# ATmega8A register map
Vendor: Atmel; File version: 1.0
CPU: other r0p0, little endian, no MPU, no FPU, 4 interrupt priority bits
Registers are 8-bit, read-write, reset 0x0 unless marked. A register's access mark holds for its fields unless they carry their own. Offsets are from the block's base; lines under a group give offsets from that group; [hi:lo] are bit positions; {n}, {i} and the like mark numbered series; 'fields as' and 'values as' point back to an identical list; <NAME> marks a mode.

## Memory map
0x00000000 FUSE size 0x2 — Fuses
0x00000000 LOCKBIT size 0x1 — Lockbits
0x00000020 TWI blocks up to offset 0x37 — Two Wire Serial Interface
0x00000024 ADC size 0x4 — Analog-to-Digital Converter
0x00000028 AC blocks up to offset 0x29 — Analog Comparator
0x00000029 USART blocks up to offset 0x18
0x0000002D SPI size 0x3 — Serial Peripheral Interface
0x00000030 PORTD size 0x3 — I/O Port
0x00000033 PORTC size 0x3 — I/O Port
0x00000036 PORTB size 0x3 — I/O Port
0x0000003C EEPROM size 0x4
0x00000041 WDT size 0x1 — Watchdog Timer
0x00000042 TC2 blocks up to offset 0x18 — Timer/Counter, 8-bit Async
0x00000046 TC1 blocks up to offset 0x14 — Timer/Counter, 16-bit
0x00000050 CPU blocks up to offset 0x8 — CPU Registers
0x00000052 TC0 blocks up to offset 0x8 — Timer/Counter, 8-bit
0x00000055 EXINT blocks up to offset 0x7 — External Interrupts

## Interrupts
0 RESET (CPU) — External Pin, Power-on Reset, Brown-out Reset and Watchdog Reset
1 INT0 (CPU) — External Interrupt Request 0
2 INT1 (CPU) — External Interrupt Request 1
3 TIMER2_COMP (CPU) — Timer/Counter2 Compare Match
4 TIMER2_OVF (CPU) — Timer/Counter2 Overflow
5 TIMER1_CAPT (CPU) — Timer/Counter1 Capture Event
6 TIMER1_COMPA (CPU) — Timer/Counter1 Compare Match A
7 TIMER1_COMPB (CPU) — Timer/Counter1 Compare Match B
8 TIMER1_OVF (CPU) — Timer/Counter1 Overflow
9 TIMER0_OVF (CPU) — Timer/Counter0 Overflow
10 SPI_STC (CPU) — Serial Transfer Complete
11 USART_RXC (CPU) — USART, Rx Complete
12 USART_UDRE (CPU) — USART Data Register Empty
13 USART_TXC (CPU) — USART, Tx Complete
14 ADC (CPU) — ADC Conversion Complete
15 EE_RDY (CPU) — EEPROM Ready
16 ANA_COMP (CPU) — Analog Comparator
17 TWI (CPU) — 2-wire Serial Interface
18 SPM_RDY (CPU) — Store Program Memory Ready

## AC — Analog Comparator
Base 0x00000028
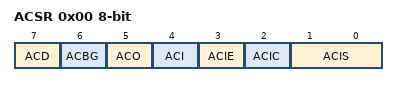
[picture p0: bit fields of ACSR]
0x00 ACSR — Analog Comparator Control And Status Register
  [7] ACD — Analog Comparator Disable
  [6] ACBG — Analog Comparator Bandgap Select
  [5] ACO — Analog Compare Output
  [4] ACI — Analog Comparator Interrupt Flag
  [3] ACIE — Analog Comparator Interrupt Enable
  [2] ACIC — Analog Comparator Input Capture Enable
  [1:0] ACIS — Analog Comparator Interrupt Mode Select bits
    0=Interrupt on Toggle; 2=Interrupt on Falling Edge; 3=Interrupt on Rising Edge
0x28 SFIOR — Special Function IO Register
  [3] ACME — Analog Comparator Multiplexer Enable

## ADC — Analog-to-Digital Converter
Base 0x00000024
0x00 ADC 16-bit (reset mask 0xFF) — ADC Data Register Bytes
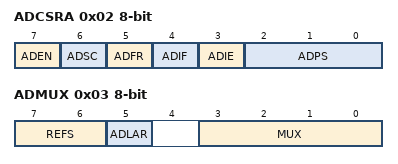
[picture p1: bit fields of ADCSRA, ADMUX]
0x02 ADCSRA — The ADC Control and Status register
  [7] ADEN — ADC Enable
  [6] ADSC — ADC Start Conversion
  [5] ADFR — ADC Free Running Select
  [4] ADIF — ADC Interrupt Flag
  [3] ADIE — ADC Interrupt Enable
  [2:0] ADPS — ADC Prescaler Select Bits
    0=2; 1=2; 2=4; 3=8; 4=16; 5=32; 6=64; 7=128
0x03 ADMUX — The ADC multiplexer Selection Register
  [7:6] REFS — Reference Selection Bits
    0=AREF, Internal Vref turned off; 1=AVCC with external capacitor at AREF pin; 3=Internal 2.56V Voltage Reference with external capacitor at AREF pin
  [5] ADLAR — Left Adjust Result
  [3:0] MUX — Analog Channel and Gain Selection Bits

## CPU — CPU Registers
Base 0x00000050
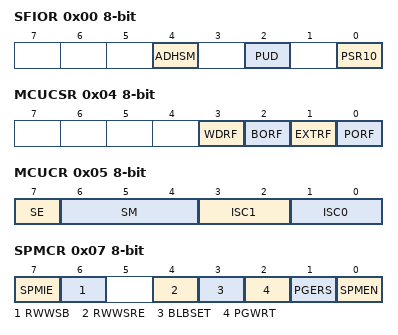
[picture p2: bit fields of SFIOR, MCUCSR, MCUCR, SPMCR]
0x00 SFIOR — Special Function IO Register
  [4] ADHSM — ADC High Speed Mode
  [2] PUD — Pull-up Disable
  [0] PSR10 — Prescaler Reset Timer/Counter1 and Timer/Counter0
0x01 OSCCAL — Oscillator Calibration Value
  [7:0] OSCCAL — Oscillator Calibration
0x04 MCUCSR — MCU Control And Status Register
  [3] WDRF — Watchdog Reset Flag
  [2] BORF — Brown-out Reset Flag
  [1] EXTRF — External Reset Flag
  [0] PORF — Power-on reset flag
0x05 MCUCR — MCU Control Register
  [7] SE — Sleep Enable
  [6:4] SM — Sleep Mode Select
    0=IDLE; 1=ADC (ADC Noise Reduction (If Available)); 2=PDOWN (Power Down); 3=PSAVE (Power Save); 6=STDBY (Standby)
  [3:2] ISC1 — Interrupt Sense Control 1 Bits
    0=Low Level of INTX; 1=Any Logical Change in INTX; 2=Falling Edge of INTX; 3=Rising Edge of INTX
  [1:0] ISC0 — Interrupt Sense Control 0 Bits
    values as ISC1
0x07 SPMCR — Store Program Memory Control Register
  [7] SPMIE — SPM Interrupt Enable
  [6] RWWSB — Read-While-Write Section Busy
  [4] RWWSRE — Read-While-Write Section Read Enable
  [3] BLBSET — Boot Lock Bit Set
  [2] PGWRT — Page Write
  [1] PGERS — Page Erase
  [0] SPMEN — Store Program Memory Enable
